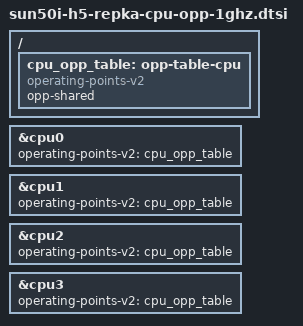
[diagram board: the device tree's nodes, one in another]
// SPDX-License-Identifier: (GPL-2.0+ OR MIT)
// Copyright (C) 2020 Chen-Yu Tsai <wens@csie.org>

/ {
	cpu_opp_table: opp-table-cpu {
		compatible = "operating-points-v2";
		opp-shared;
	};
};

&cpu0 {
	operating-points-v2 = <&cpu_opp_table>;
};

&cpu1 {
	operating-points-v2 = <&cpu_opp_table>;
};

&cpu2 {
	operating-points-v2 = <&cpu_opp_table>;
};

&cpu3 {
	operating-points-v2 = <&cpu_opp_table>;
};
